# STM32H5E5xx register map
File version: 1.0
Registers are 32-bit, read-write, reset 0x0 unless marked. A register's access mark holds for its fields unless they carry their own. Offsets are from the block's base; [hi:lo] are bit positions.

## FDCAN3 — FD Controller Area Network
Base 0x4000A000
Same registers: FDCAN1 0x4000A400, FDCAN2 0x4000A800, FDCAN3_S 0x5000A000, FDCAN1_S 0x5000A400, FDCAN2_S 0x5000A800
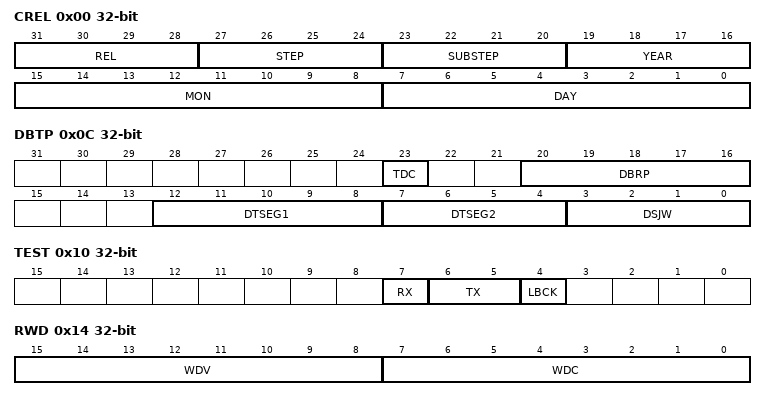
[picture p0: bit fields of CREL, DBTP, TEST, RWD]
0x00 CREL — FDCAN Core Release register
  [31:28] REL — Core release
  [27:24] STEP — Step of Core release
  [23:20] SUBSTEP — Sub-step of Core release
  [19:16] YEAR — Timestamp Year
  [15:8] MON — Timestamp Month
  [7:0] DAY — Timestamp Day
0x04 ENDN — FDCAN Endian register
  [31:0] ETV — Endianness Test Value
0x0C DBTP — FDCAN Data Bit Timing & Prescaler register
  [23] TDC — Transceiver Delay Compensation
  [20:16] DBRP — Data BIt Rate Prescaler
  [12:8] DTSEG1 — Data time segment before sample point
  [7:4] DTSEG2 — Data time segment after sample point
  [3:0] DSJW — Synchronization Jump Width
0x10 TEST — FDCAN Test register
  [7] RX — Receive Pin
  [6:5] TX — Control of Transmit Pin
  [4] LBCK — Loop Back mode
0x14 RWD — FDCAN RAM Watchdog register
  [15:8] WDV — Watchdog value
  [7:0] WDC — Watchdog configuration
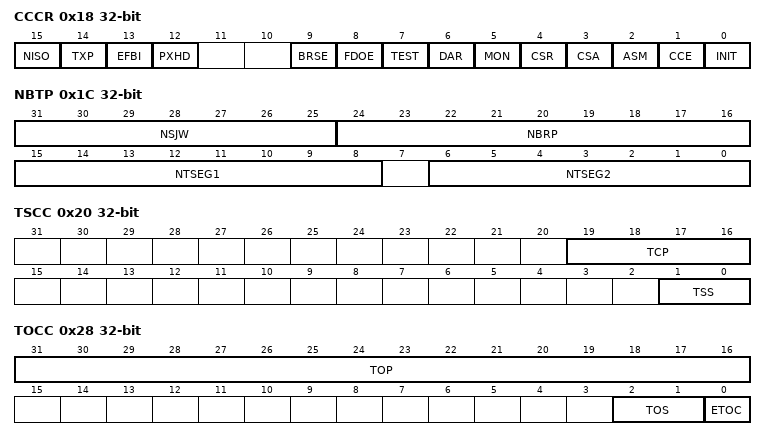
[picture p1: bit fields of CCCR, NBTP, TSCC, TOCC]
0x18 CCCR — FDCAN CC Control register
  [15] NISO — Non ISO Operation
  [14] TXP — Two CAN bit times Pause
  [13] EFBI — Edge Filtering during Bus Integration
  [12] PXHD — Protocol Exception Handling Disable
  [9] BRSE — FDCAN Bit Rate Switching
  [8] FDOE — FD Operation Enable
  [7] TEST — Test Mode Enable
  [6] DAR — Disable Automatic Retransmission
  [5] MON — Bus Monitoring Mode
  [4] CSR — Clock Stop Request
  [3] CSA — Clock Stop Acknowledge
  [2] ASM — ASM Restricted Operation Mode
  [1] CCE — Configuration Change Enable
  [0] INIT — Initialization
0x1C NBTP — FDCAN Nominal Bit Timing & Prescaler register
  [31:25] NSJW — Nominal (Re)Synchronization Jump Width
  [24:16] NBRP — Bit Rate Prescaler
  [15:8] NTSEG1 — Nominal Time segment before sample point
  [6:0] NTSEG2 — Nominal Time segment after sample point
0x20 TSCC — FDCAN Timestamp Counter Configuration register
  [19:16] TCP — Timestamp Counter Prescaler
  [1:0] TSS — Timestamp Select
0x24 TSCV — FDCAN Timestamp Counter Value register
  [15:0] TSC — Timestamp Counter
0x28 TOCC — FDCAN Timeout Counter Configuration register
  [31:16] TOP — Timeout Period
  [2:1] TOS — Timeout Select
  [0] ETOC — Enable Timeout Counter
0x2C TOCV — FDCAN Timeout Counter Value register
  [15:0] TOC — Timeout Counter
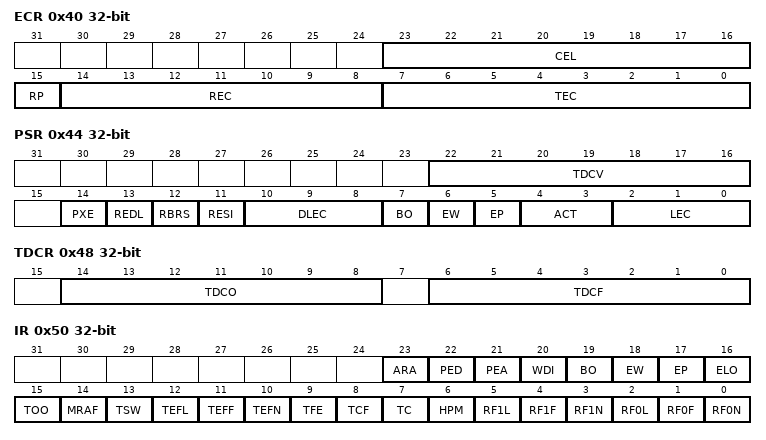
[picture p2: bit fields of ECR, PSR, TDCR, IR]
0x40 ECR — FDCAN Error Counter register
  [23:16] CEL — CAN Error Logging
  [15] RP — Receive Error Passive
  [14:8] REC — Receive Error Counter
  [7:0] TEC — Transmit Error Counter
0x44 PSR — FDCAN Protocol Status register
  [22:16] TDCV — Transmitter Delay Compensation Value
  [14] PXE — Protocol Exception Event
  [13] REDL — Received FDCAN Message
  [12] RBRS — BRS flag of last received FDCAN Message
  [11] RESI — ESI flag of last received FDCAN Message
  [10:8] DLEC — Data Last Error Code
  [7] BO — Bus_Off Status
  [6] EW — Warning Status
  [5] EP — Error Passive
  [4:3] ACT — Activity
  [2:0] LEC — Last Error Code
0x48 TDCR — FDCAN Transmitter Delay Compensation register
  [14:8] TDCO — Transmitter Delay Compensation Offset
  [6:0] TDCF — Transmitter Delay Compensation Filter
0x50 IR — FDCAN Interrupt register
  [23] ARA — Access to Reserved Address
  [22] PED — Protocol Error in Data Phase
  [21] PEA — Protocol Error in Arbitration Phase
  [20] WDI — Watchdog Interrupt
  [19] BO — Bus_Off Status
  [18] EW — Warning Status
  [17] EP — Error Passive
  [16] ELO — Error Logging Overflow
  [15] TOO — Timeout Occurred
  [14] MRAF — Message RAM Access Failure
  [13] TSW — Timestamp Wraparound
  [12] TEFL — Tx Event FIFO Element Lost
  [11] TEFF — Tx Event FIFO Full
  [10] TEFN — Tx Event FIFO New Entry
  [9] TFE — Tx FIFO Empty
  [8] TCF — Transmission Cancellation Finished
  [7] TC — Transmission Completed
  [6] HPM — High Priority Message
  [5] RF1L — Rx FIFO 1 Message Lost
  [4] RF1F — Rx FIFO 1 Full
  [3] RF1N — Rx FIFO 1 New Message
  [2] RF0L — Rx FIFO 0 Message Lost
  [1] RF0F — Rx FIFO 0 Full
  [0] RF0N — Rx FIFO 0 New Message
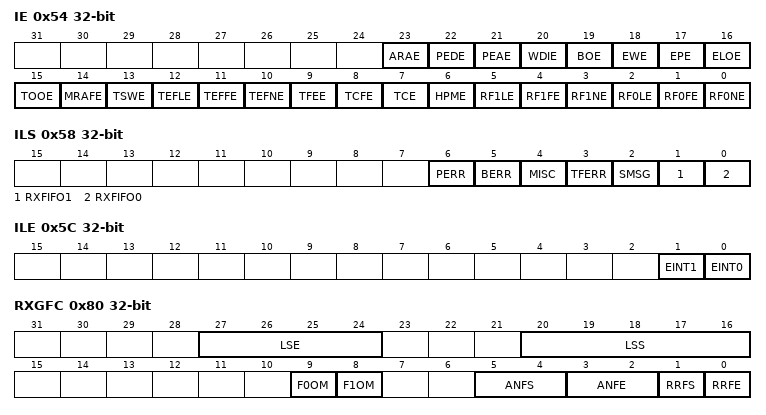
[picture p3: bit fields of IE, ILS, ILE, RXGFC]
0x54 IE — FDCAN Interrupt Enable register
  [23] ARAE — Access to Reserved Address Enable
  [22] PEDE — Protocol Error in Data Phase Enable
  [21] PEAE — Protocol Error in Arbitration Phase Enable
  [20] WDIE — Watchdog Interrupt Enable
  [19] BOE — Bus_Off Status Enable
  [18] EWE — Warning Status Enable
  [17] EPE — Error Passive Enable
  [16] ELOE — Error Logging Overflow Enable
  [15] TOOE — Timeout Occurred Enable
  [14] MRAFE — Message RAM Access Failure Enable
  [13] TSWE — Timestamp Wraparound Enable
  [12] TEFLE — Tx Event FIFO Element Lost Enable
  [11] TEFFE — Tx Event FIFO Full Enable
  [10] TEFNE — Tx Event FIFO New Entry Enable
  [9] TFEE — Tx FIFO Empty Enable
  [8] TCFE — Transmission Cancellation Finished Enable
  [7] TCE — Transmission Completed Enable
  [6] HPME — High Priority Message Enable
  [5] RF1LE — Rx FIFO 1 Message Lost Enable
  [4] RF1FE — Rx FIFO 1 Full Enable
  [3] RF1NE — Rx FIFO 1 New Message Enable
  [2] RF0LE — Rx FIFO 0 Message Lost Enable
  [1] RF0FE — Rx FIFO 0 Full Enable
  [0] RF0NE — Rx FIFO 0 New Message Enable
0x58 ILS — FDCAN Interrupt Line Select register
  [6] PERR, [5] BERR, [4] MISC, [3] TFERR, [2] SMSG, [1] RXFIFO1, [0] RXFIFO0
0x5C ILE — FDCAN Interrupt Line Enable register
  [1] EINT1 — Enable Interrupt Line 1
  [0] EINT0 — Enable Interrupt Line 0
0x80 RXGFC — FDCAN Global Filter Configuration register
  [27:24] LSE — List Size Extended
  [20:16] LSS — List Size Standard
  [9] F0OM — FIFO 0 operation mode
  [8] F1OM — FIFO 1 operation mode
  [5:4] ANFS — Accept Non-matching Frames Standard
  [3:2] ANFE — Accept Non-matching Frames Extended
  [1] RRFS — Reject Remote Frames Standard
  [0] RRFE — Reject Remote Frames Extended
0x84 XIDAM — FDCAN Extended ID AND Mask register
  [28:0] EIDM — Extended ID Mask
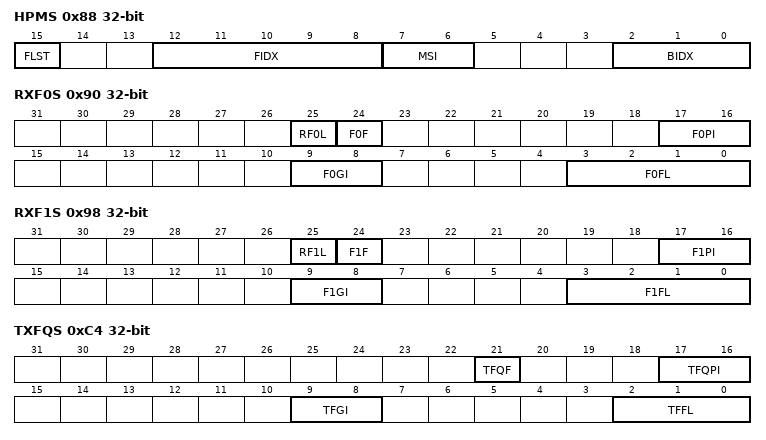
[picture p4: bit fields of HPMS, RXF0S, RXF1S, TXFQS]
0x88 HPMS — FDCAN High Priority Message Status register
  [15] FLST — Filter List
  [12:8] FIDX — Filter Index
  [7:6] MSI — Message Storage Indicator
  [2:0] BIDX — Buffer Index
0x90 RXF0S — FDCAN Rx FIFO 0 Status register
  [25] RF0L — Rx FIFO 0 Message Lost
  [24] F0F — Rx FIFO 0 Full
  [17:16] F0PI — Rx FIFO 0 Put Index
  [9:8] F0GI — Rx FIFO 0 Get Index
  [3:0] F0FL — Rx FIFO 0 Fill Level
0x94 RXF0A — FDCAN Rx FIFO 0 Acknowledge register
  [2:0] F0AI — Rx FIFO 0 Acknowledge Index
0x98 RXF1S — FDCAN Rx FIFO 1 Status register
  [25] RF1L — Rx FIFO 1 Message Lost
  [24] F1F — Rx FIFO 1 Full
  [17:16] F1PI — Rx FIFO 1 Put Index
  [9:8] F1GI — Rx FIFO 1 Get Index
  [3:0] F1FL — Rx FIFO 1 Fill Level
0x9C RXF1A — FDCAN Rx FIFO 1 Acknowledge register
  [2:0] F1AI — Rx FIFO 1 Acknowledge Index
0xC0 TXBC — FDCAN Tx Buffer Configuration register
  [24] TFQM — Tx FIFO/Queue Mode
0xC4 TXFQS — FDCAN Tx FIFO/Queue Status register
  [21] TFQF — Tx FIFO/Queue Full
  [17:16] TFQPI — Tx FIFO/Queue Put Index
  [9:8] TFGI — Tx FIFO Get Index
  [2:0] TFFL — Tx FIFO Free Level
0xC8 TXBRP — FDCAN Tx Buffer Request Pending register
  [2:0] TRP — Transmission Request Pending
0xCC TXBAR — FDCAN Tx Buffer Add Request register
  [2:0] AR — Add Request
0xD0 TXBCR — FDCAN Tx Buffer Cancellation Request register
  [2:0] CR — Cancellation Request
0xD4 TXBTO — FDCAN Tx Buffer Transmission Occurred register
  [2:0] TO — Transmission Occurred
0xD8 TXBCF — FDCAN Tx Buffer Cancellation Finished register
  [2:0] CF — Cancellation Finished
0xDC TXBTIE — FDCAN Tx Buffer Transmission Interrupt Enable register
  [2:0] TIE — Transmission Interrupt Enable
0xE0 TXBCIE — FDCAN Tx Buffer Cancellation Finished Interrupt Enable register
  [2:0] CFIE — Cancellation Finished Interrupt Enable
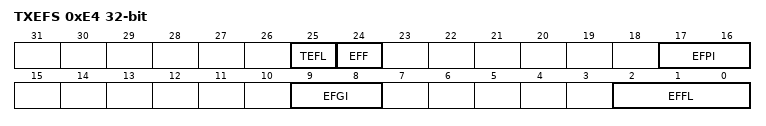
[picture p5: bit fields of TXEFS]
0xE4 TXEFS — FDCAN Tx Event FIFO Status register
  [25] TEFL — Tx Event FIFO Element Lost
  [24] EFF — Event FIFO Full
  [17:16] EFPI — Event FIFO Put Index
  [9:8] EFGI — Event FIFO Get Index
  [2:0] EFFL — Event FIFO Fill Level
0xE8 TXEFA — FDCAN Tx Event FIFO Acknowledge register
  [1:0] EFAI — Event FIFO Acknowledge Index
